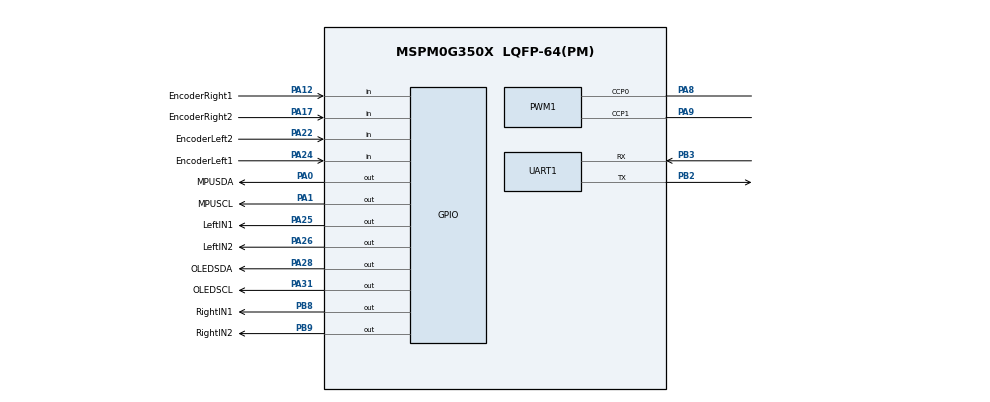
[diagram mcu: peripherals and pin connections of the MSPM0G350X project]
/**
 * @cliArgs --device "MSPM0G350X" --package "LQFP-64(PM)" --part "Default" --product "mspm0_sdk@2.01.00.03"
 * @versions {"tool":"1.20.0+3587"}
 */

/**
 * Import the modules used in this configuration.
 */
const ADC12  = scripting.addModule("/ti/driverlib/ADC12", {}, false);
const ADC121 = ADC12.addInstance();
const GPIO   = scripting.addModule("/ti/driverlib/GPIO", {}, false);
const GPIO1  = GPIO.addInstance();
const GPIO2  = GPIO.addInstance();
const GPIO3  = GPIO.addInstance();
const GPIO4  = GPIO.addInstance();
const PWM    = scripting.addModule("/ti/driverlib/PWM", {}, false);
const PWM1   = PWM.addInstance();
const SYSCTL = scripting.addModule("/ti/driverlib/SYSCTL");
const TIMER  = scripting.addModule("/ti/driverlib/TIMER", {}, false);
const TIMER1 = TIMER.addInstance();
const TIMER2 = TIMER.addInstance();
const UART   = scripting.addModule("/ti/driverlib/UART", {}, false);
const UART1  = UART.addInstance();

/**
 * Write custom configuration values to the imported modules.
 */
const gate7  = system.clockTree["MFCLKGATE"];
gate7.enable = true;

ADC121.sampClkDiv                        = "DL_ADC12_CLOCK_DIVIDE_8";
ADC121.adcMem3_name                      = "infraredRight";
ADC121.adcMem1chansel                    = "DL_ADC12_INPUT_CHAN_1";
ADC121.adcMem3chansel                    = "DL_ADC12_INPUT_CHAN_3";
ADC121.sampCnt                           = 3;
ADC121.enabledDMATriggers                = ["DL_ADC12_DMA_MEM1_RESULT_LOADED","DL_ADC12_DMA_MEM2_RESULT_LOADED","DL_ADC12_DMA_MEM3_RESULT_LOADED"];
ADC121.$name                             = "infraredADC";
ADC121.interruptPriority                 = "1";
ADC121.samplingOperationMode             = "sequence";
ADC121.repeatMode                        = true;
ADC121.adcMem0_name                      = "infraredLeft";
ADC121.adcMem1_name                      = "infraredCenter";
ADC121.adcMem2_name                      = "infraredRight";
ADC121.adcMem5chansel                    = "DL_ADC12_INPUT_CHAN_5";
ADC121.adcMem5_name                      = "infraredLeft";
ADC121.endAdd                            = 2;
ADC121.adcMem2chansel                    = "DL_ADC12_INPUT_CHAN_5";
ADC121.enabledInterrupts                 = ["DL_ADC12_INTERRUPT_MEM2_RESULT_LOADED"];
ADC121.sampleTime0                       = "10 ms";
ADC121.peripheral.$assign                = "ADC1";
ADC121.peripheral.adcPin0.$assign        = "PA15";
ADC121.peripheral.adcPin1.$assign        = "PA16";
ADC121.peripheral.adcPin5.$assign        = "PB18";
ADC121.adcPin0Config.hideOutputInversion = scripting.forceWrite(false);
ADC121.adcPin0Config.$name               = "ti_driverlib_gpio_GPIOPinGeneric4";
ADC121.adcPin1Config.$name               = "ti_driverlib_gpio_GPIOPinGeneric6";
ADC121.adcPin5Config.$name               = "ti_driverlib_gpio_GPIOPinGeneric5";

const Board = scripting.addModule("/ti/driverlib/Board", {}, false);

GPIO1.$name                          = "OLED";
GPIO1.associatedPins.create(2);
GPIO1.associatedPins[0].$name        = "OLEDSDA";
GPIO1.associatedPins[0].initialValue = "SET";
GPIO1.associatedPins[0].assignedPort = "PORTA";
GPIO1.associatedPins[0].assignedPin  = "28";
GPIO1.associatedPins[0].pin.$assign  = "PA28";
GPIO1.associatedPins[1].$name        = "OLEDSCL";
GPIO1.associatedPins[1].initialValue = "SET";
GPIO1.associatedPins[1].assignedPort = "PORTA";
GPIO1.associatedPins[1].assignedPin  = "31";
GPIO1.associatedPins[1].pin.$assign  = "PA31";

GPIO2.$name                          = "MotorIN";
GPIO2.associatedPins.create(4);
GPIO2.associatedPins[0].$name        = "LeftIN1";
GPIO2.associatedPins[0].assignedPort = "PORTA";
GPIO2.associatedPins[0].assignedPin  = "25";
GPIO2.associatedPins[0].pin.$assign  = "PA25";
GPIO2.associatedPins[1].$name        = "LeftIN2";
GPIO2.associatedPins[1].assignedPort = "PORTA";
GPIO2.associatedPins[1].assignedPin  = "26";
GPIO2.associatedPins[1].pin.$assign  = "PA26";
GPIO2.associatedPins[2].$name        = "RightIN1";
GPIO2.associatedPins[2].assignedPort = "PORTB";
GPIO2.associatedPins[2].assignedPin  = "8";
GPIO2.associatedPins[2].pin.$assign  = "PB8";
GPIO2.associatedPins[3].$name        = "RightIN2";
GPIO2.associatedPins[3].assignedPort = "PORTB";
GPIO2.associatedPins[3].assignedPin  = "9";
GPIO2.associatedPins[3].pin.$assign  = "PB9";

GPIO3.$name                               = "Encoder";
GPIO3.associatedPins.create(4);
GPIO3.associatedPins[0].direction         = "INPUT";
GPIO3.associatedPins[0].interruptEn       = true;
GPIO3.associatedPins[0].$name             = "EncoderLeft1";
GPIO3.associatedPins[0].assignedPort      = "PORTA";
GPIO3.associatedPins[0].interruptPriority = "1";
GPIO3.associatedPins[0].internalResistor  = "PULL_DOWN";
GPIO3.associatedPins[0].polarity          = "RISE_FALL";
GPIO3.associatedPins[0].inputFilter       = "8_CYCLES";
GPIO3.associatedPins[0].assignedPin       = "24";
GPIO3.associatedPins[0].pin.$assign       = "PA24";
GPIO3.associatedPins[1].$name             = "EncoderLeft2";
GPIO3.associatedPins[1].direction         = "INPUT";
GPIO3.associatedPins[1].interruptEn       = true;
GPIO3.associatedPins[1].assignedPort      = "PORTA";
GPIO3.associatedPins[1].interruptPriority = "1";
GPIO3.associatedPins[1].internalResistor  = "PULL_DOWN";
GPIO3.associatedPins[1].polarity          = "RISE_FALL";
GPIO3.associatedPins[1].inputFilter       = "8_CYCLES";
GPIO3.associatedPins[1].assignedPin       = "22";
GPIO3.associatedPins[1].pin.$assign       = "PA22";
GPIO3.associatedPins[2].$name             = "EncoderRight1";
GPIO3.associatedPins[2].direction         = "INPUT";
GPIO3.associatedPins[2].interruptEn       = true;
GPIO3.associatedPins[2].assignedPort      = "PORTA";
GPIO3.associatedPins[2].interruptPriority = "1";
GPIO3.associatedPins[2].internalResistor  = "PULL_DOWN";
GPIO3.associatedPins[2].polarity          = "RISE_FALL";
GPIO3.associatedPins[2].inputFilter       = "8_CYCLES";
GPIO3.associatedPins[2].assignedPin       = "12";
GPIO3.associatedPins[2].pin.$assign       = "PA12";
GPIO3.associatedPins[3].$name             = "EncoderRight2";
GPIO3.associatedPins[3].direction         = "INPUT";
GPIO3.associatedPins[3].interruptEn       = true;
GPIO3.associatedPins[3].assignedPort      = "PORTA";
GPIO3.associatedPins[3].interruptPriority = "1";
GPIO3.associatedPins[3].internalResistor  = "PULL_DOWN";
GPIO3.associatedPins[3].polarity          = "RISE_FALL";
GPIO3.associatedPins[3].inputFilter       = "8_CYCLES";
GPIO3.associatedPins[3].assignedPin       = "17";
GPIO3.associatedPins[3].pin.$assign       = "PA17";

GPIO4.$name                          = "MPU";
GPIO4.associatedPins.create(2);
GPIO4.associatedPins[0].$name        = "MPUSCL";
GPIO4.associatedPins[0].ioStructure  = "OD";
GPIO4.associatedPins[0].initialValue = "SET";
GPIO4.associatedPins[0].assignedPort = "PORTA";
GPIO4.associatedPins[0].assignedPin  = "1";
GPIO4.associatedPins[0].pin.$assign  = "PA1";
GPIO4.associatedPins[1].$name        = "MPUSDA";
GPIO4.associatedPins[1].ioStructure  = "OD";
GPIO4.associatedPins[1].initialValue = "SET";
GPIO4.associatedPins[1].assignedPort = "PORTA";
GPIO4.associatedPins[1].assignedPin  = "0";
GPIO4.associatedPins[1].pin.$assign  = "PA0";

PWM1.clockDivider                       = 8;
PWM1.timerCount                         = 7200;
PWM1.timerStartTimer                    = true;
PWM1.$name                              = "MotorPWM";
PWM1.pwmMode                            = "EDGE_ALIGN_UP";
PWM1.peripheral.$assign                 = "TIMA0";
PWM1.peripheral.ccp0Pin.$assign         = "PA8";
PWM1.peripheral.ccp1Pin.$assign         = "PA9";
PWM1.PWM_CHANNEL_0.$name                = "ti_driverlib_pwm_PWMTimerCC0";
PWM1.PWM_CHANNEL_1.$name                = "ti_driverlib_pwm_PWMTimerCC1";
PWM1.ccp0PinConfig.direction            = scripting.forceWrite("OUTPUT");
PWM1.ccp0PinConfig.hideOutputInversion  = scripting.forceWrite(false);
PWM1.ccp0PinConfig.onlyInternalResistor = scripting.forceWrite(false);
PWM1.ccp0PinConfig.passedPeripheralType = scripting.forceWrite("Digital");
PWM1.ccp0PinConfig.$name                = "ti_driverlib_gpio_GPIOPinGeneric0";
PWM1.ccp1PinConfig.direction            = scripting.forceWrite("OUTPUT");
PWM1.ccp1PinConfig.hideOutputInversion  = scripting.forceWrite(false);
PWM1.ccp1PinConfig.onlyInternalResistor = scripting.forceWrite(false);
PWM1.ccp1PinConfig.passedPeripheralType = scripting.forceWrite("Digital");
PWM1.ccp1PinConfig.$name                = "ti_driverlib_gpio_GPIOPinGeneric1";

SYSCTL.forceDefaultClkConfig = true;
SYSCTL.clockTreeEn           = true;

TIMER1.timerClkDiv        = 8;
TIMER1.timerClkPrescale   = 100;
TIMER1.timerMode          = "PERIODIC";
TIMER1.timerPeriod        = "10 ms";
TIMER1.timerStartTimer    = true;
TIMER1.interrupts         = ["ZERO"];
TIMER1.$name              = "taskTimer";
TIMER1.interruptPriority  = "3";
TIMER1.peripheral.$assign = "TIMG0";

TIMER2.$name              = "msTimer";
TIMER2.timerClkDiv        = 8;
TIMER2.timerClkPrescale   = 100;
TIMER2.timerMode          = "PERIODIC";
TIMER2.timerPeriod        = "1 ms";
TIMER2.timerStartTimer    = true;
TIMER2.interrupts         = ["ZERO"];
TIMER2.interruptPriority  = "0";
TIMER2.peripheral.$assign = "TIMG6";

UART1.uartClkSrc                       = "MFCLK";
UART1.$name                            = "Bluetooth";
UART1.interruptPriority                = "0";
UART1.enabledInterrupts                = ["RX"];
UART1.peripheral.$assign               = "UART3";
UART1.peripheral.rxPin.$assign         = "PB3";
UART1.peripheral.txPin.$assign         = "PB2";
UART1.txPinConfig.direction            = scripting.forceWrite("OUTPUT");
UART1.txPinConfig.hideOutputInversion  = scripting.forceWrite(false);
UART1.txPinConfig.onlyInternalResistor = scripting.forceWrite(false);
UART1.txPinConfig.passedPeripheralType = scripting.forceWrite("Digital");
UART1.txPinConfig.$name                = "ti_driverlib_gpio_GPIOPinGeneric2";
UART1.rxPinConfig.hideOutputInversion  = scripting.forceWrite(false);
UART1.rxPinConfig.onlyInternalResistor = scripting.forceWrite(false);
UART1.rxPinConfig.passedPeripheralType = scripting.forceWrite("Digital");
UART1.rxPinConfig.$name                = "ti_driverlib_gpio_GPIOPinGeneric3";

/**
 * Pinmux solution for unlocked pins/peripherals. This ensures that minor changes to the automatic solver in a future
 * version of the tool will not impact the pinmux you originally saw.  These lines can be completely deleted in order to
 * re-solve from scratch.
 */
Board.peripheral.$suggestSolution          = "DEBUGSS";
Board.peripheral.swclkPin.$suggestSolution = "PA20";
Board.peripheral.swdioPin.$suggestSolution = "PA19";
